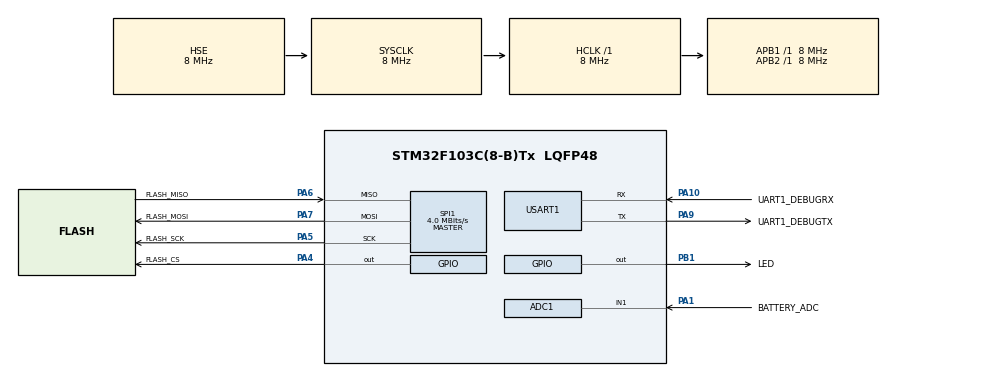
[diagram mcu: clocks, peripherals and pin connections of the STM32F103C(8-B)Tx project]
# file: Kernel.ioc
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ADC1.Channel-0\#ChannelRegularConversion=ADC_CHANNEL_1
ADC1.NbrOfConversionFlag=1
ADC1.Rank-0\#ChannelRegularConversion=1
ADC1.SamplingTime-0\#ChannelRegularConversion=ADC_SAMPLETIME_1CYCLE_5
ADC1.master=1
IWDG.Prescaler=IWDG_PRESCALER_32
Mcu.Family=STM32F1
Mcu.Name=STM32F103C(8-B)Tx
Mcu.Package=LQFP48
NVIC.PriorityGroup=NVIC_PRIORITYGROUP_4
PA1.GPIO_Label=BATTERY_ADC
PA1.Signal=ADCx_IN1
PA10.GPIO_Label=UART1_DEBUGRX
PA10.Mode=Asynchronous
PA10.Signal=USART1_RX
PA13.Mode=Serial_Wire
PA13.Signal=SYS_JTMS-SWDIO
PA14.Mode=Serial_Wire
PA14.Signal=SYS_JTCK-SWCLK
PA4.GPIO_Label=FLASH_CS
PA4.Signal=GPIO_Output
PA5.GPIO_Label=FLASH_SCK
PA5.Mode=Full_Duplex_Master
PA5.Signal=SPI1_SCK
PA6.GPIO_Label=FLASH_MISO
PA6.Mode=Full_Duplex_Master
PA6.Signal=SPI1_MISO
PA7.GPIO_Label=FLASH_MOSI
PA7.Mode=Full_Duplex_Master
PA7.Signal=SPI1_MOSI
PA9.GPIO_Label=UART1_DEBUGTX
PA9.Mode=Asynchronous
PA9.Signal=USART1_TX
PB1.GPIO_Label=LED
PB1.Signal=GPIO_Output
PD0-OSC_IN.Mode=HSE-External-Oscillator
PD0-OSC_IN.Signal=RCC_OSC_IN
PD1-OSC_OUT.Mode=HSE-External-Oscillator
PD1-OSC_OUT.Signal=RCC_OSC_OUT
ProjectManager.HeapSize=0x200
ProjectManager.StackSize=0x400
ProjectManager.TargetToolchain=STM32CubeIDE
RCC.AHBFreq_Value=8000000
RCC.APB1Freq_Value=8000000
RCC.APB1TimFreq_Value=8000000
RCC.APB2Freq_Value=8000000
RCC.APB2TimFreq_Value=8000000
RCC.HCLKFreq_Value=8000000
RCC.PLLMUL=RCC_PLL_MUL6
RCC.PLLSourceVirtual=RCC_PLLSOURCE_HSE
RCC.SYSCLKFreq_VALUE=8000000
RCC.SYSCLKSource=RCC_SYSCLKSOURCE_HSE
RCC.USBFreq_Value=48000000
SH.ADCx_IN1.0=ADC1_IN1,IN1
SPI1.CalculateBaudRate=4.0 MBits/s
SPI1.Direction=SPI_DIRECTION_2LINES
SPI1.Mode=SPI_MODE_MASTER
SPI1.VirtualType=VM_MASTER
USART1.VirtualMode=VM_ASYNC
VP_IWDG_VS_IWDG.Mode=IWDG_Activate
board=custom

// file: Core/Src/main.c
/* USER CODE BEGIN Header */
/**
 ******************************************************************************
 * @file           : main.c
 * @brief          : Main program body
 ******************************************************************************
 * @attention
 *
 * Copyright (c) 2023 STMicroelectronics.
 * All rights reserved.
 *
 * This software is licensed under terms that can be found in the LICENSE file
 * in the root directory of this software component.
 * If no LICENSE file comes with this software, it is provided AS-IS.
 *
 ******************************************************************************
 */
/* USER CODE END Header */
#include "main.h"
#include "adc.h"
#include "iwdg.h"
#include "spi.h"
#include "usart.h"
#include "gpio.h"

/* USER CODE BEGIN Includes */
#include "sys.h"
/* USER CODE END Includes */

void SystemClock_Config(void);

int main(void)
{

	/* MCU Configuration--------------------------------------------------------*/

	/* Reset of all peripherals, Initializes the Flash interface and the Systick. */
	HAL_Init();

	/* Configure the system clock */
	SystemClock_Config();

	/* Initialize all configured peripherals */
	MX_GPIO_Init();
	MX_IWDG_Init();
	MX_SPI1_Init();
	MX_USART1_UART_Init();
	MX_ADC1_Init();
	/* USER CODE BEGIN 2 */

	/* Initialize the kernel */
	sys_firstInit();

	/* USER CODE END 2 */

	/* Infinite loop */
	/* USER CODE BEGIN WHILE */
	while (1)
	{
		/* Run the kernel */
		sys();

		/* From this point, everything in the system should be handled using the Interface functions.
		 *
		 * Edit the system_setup.h file to add/remove features.
		 *
		 * Follow the guide below to add different libraries to the system:
		 *
		 * 1. add the library_addTimer() function to the ../Core/Src/Interface/interface_systemClock() function.
		 * 2. add the library_dataStructure to the interfaceDataStructure_t of ../Core/Src/Interface/int_fetchData
		 * 3. add the fetchData function to add a copy of the data structure to the interfaceDataStructure_t of ../Core/Src/Interface/int_fetchData
		 * 4. add the main function to the ../Core/Src/Interface/int_task.
		 * 5. add the initialization function to the ../Core/Src/Interface/int_firstInit.
		 * 6. add the interrupt handlers as stated in the library.	   *
		 *
		 * */
		/* USER CODE END WHILE */

	}
}

void SystemClock_Config(void)
{
	RCC_OscInitTypeDef RCC_OscInitStruct = {0};
	RCC_ClkInitTypeDef RCC_ClkInitStruct = {0};
	RCC_PeriphCLKInitTypeDef PeriphClkInit = {0};

	/** Initializes the RCC Oscillators according to the specified parameters
	 * in the RCC_OscInitTypeDef structure.
	 */
	RCC_OscInitStruct.OscillatorType = RCC_OSCILLATORTYPE_LSI|RCC_OSCILLATORTYPE_HSE;
	RCC_OscInitStruct.HSEState = RCC_HSE_ON;
	RCC_OscInitStruct.LSIState = RCC_LSI_ON;
	RCC_OscInitStruct.PLL.PLLState = RCC_PLL_NONE;
	if (HAL_RCC_OscConfig(&RCC_OscInitStruct) != HAL_OK)
	{
		Error_Handler();
	}

	/** Initializes the CPU, AHB and APB buses clocks
	 */
	RCC_ClkInitStruct.ClockType = RCC_CLOCKTYPE_HCLK|RCC_CLOCKTYPE_SYSCLK
			|RCC_CLOCKTYPE_PCLK1|RCC_CLOCKTYPE_PCLK2;
	RCC_ClkInitStruct.SYSCLKSource = RCC_SYSCLKSOURCE_HSE;
	RCC_ClkInitStruct.AHBCLKDivider = RCC_SYSCLK_DIV1;
	RCC_ClkInitStruct.APB1CLKDivider = RCC_HCLK_DIV1;
	RCC_ClkInitStruct.APB2CLKDivider = RCC_HCLK_DIV1;

	if (HAL_RCC_ClockConfig(&RCC_ClkInitStruct, FLASH_LATENCY_0) != HAL_OK)
	{
		Error_Handler();
	}
	PeriphClkInit.PeriphClockSelection = RCC_PERIPHCLK_ADC;
	PeriphClkInit.AdcClockSelection = RCC_ADCPCLK2_DIV2;
	if (HAL_RCCEx_PeriphCLKConfig(&PeriphClkInit) != HAL_OK)
	{
		Error_Handler();
	}
}

void Error_Handler(void)
{
	__disable_irq();
	while (1)
	{
	}
}
